# AST1080 register map
File version: 1.0
CPU: CM4 r0p1, little endian, MPU, FPU, 4 interrupt priority bits, 256 interrupts
Registers are 32-bit, read-write, reset 0x0 unless marked. A register's access mark holds for its fields unless they carry their own. Offsets are from the block's base; [hi:lo] are bit positions; {n}, {i} and the like mark numbered series; 'fields as' and 'values as' point back to an identical list.

## uartdma
Base 0x74C12000
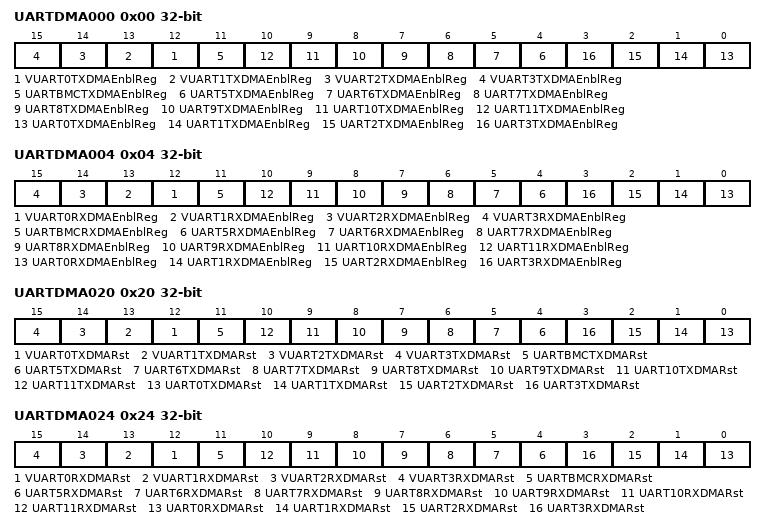
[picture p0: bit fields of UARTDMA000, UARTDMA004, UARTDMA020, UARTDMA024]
0x00 UARTDMA000 — UART TX DMA enable
  [n+12] VUART{n}TXDMAEnblReg (n=0..3) — VUART{n} TX DMA enable register
  [11] UARTBMCTXDMAEnblReg — UART-BMC TX DMA enable register
  [n-1] UART{n}TXDMAEnblReg (n=5..11) — UART{n} TX DMA enable register
  [n] UART{n}TXDMAEnblReg (n=0..3) — UART{n} TX DMA enable register
0x04 UARTDMA004 — UART RX DMA enable
  [n+12] VUART{n}RXDMAEnblReg (n=0..3) — VUART{n} RX DMA enable register
  [11] UARTBMCRXDMAEnblReg — UART-BMC RX DMA enable register
  [n-1] UART{n}RXDMAEnblReg (n=5..11) — UART{n} RX DMA enable register
  [n] UART{n}RXDMAEnblReg (n=0..3) — UART{n} RX DMA enable register
0x08 UARTDMA008 — Misc control
  [4] DisableTimeOut
    0=Enable_Time_Out_Timer; 1=Disable_Time_Out_Timer
0x0C UARTDMA00C — UART DMA time out timer
  [15:0] UARTDMATimeOutTimer
0x20 UARTDMA020 — UART TX DMA reset
  [n+12] VUART{n}TXDMARst (n=0..3) — VUART{n} TX DMA reset
  [11] UARTBMCTXDMARst — UART-BMC TX DMA reset
  [n-1] UART{n}TXDMARst (n=5..11) — UART{n} TX DMA reset
  [n] UART{n}TXDMARst (n=0..3) — UART{n} TX DMA reset
0x24 UARTDMA024 — UART RX DMA reset
  [n+12] VUART{n}RXDMARst (n=0..3) — VUART{n} RX DMA reset
  [11] UARTBMCRXDMARst — UART-BMC RX DMA reset
  [n-1] UART{n}RXDMARst (n=5..11) — UART{n} RX DMA reset
  [n] UART{n}RXDMARst (n=0..3) — UART{n} RX DMA reset
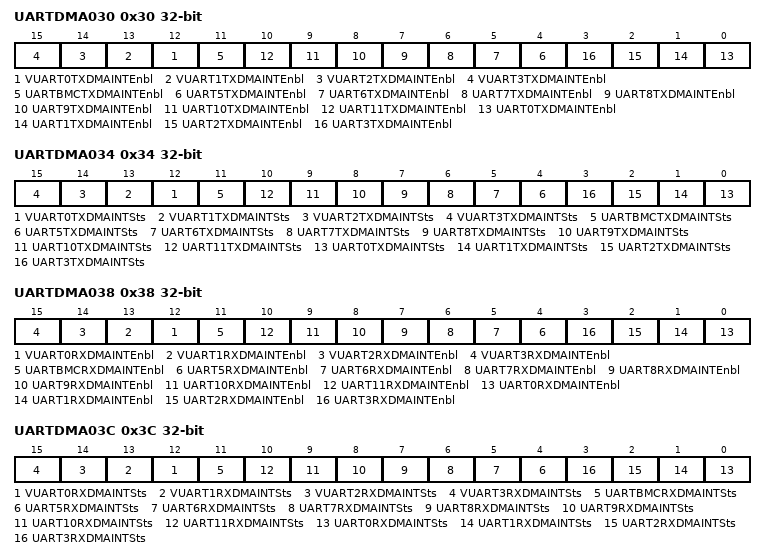
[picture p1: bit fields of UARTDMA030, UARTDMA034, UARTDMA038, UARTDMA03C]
0x30 UARTDMA030 — UART TX DMA interrrupt enable
  [n+12] VUART{n}TXDMAINTEnbl (n=0..3) — VUART{n} TX DMA interrupt enable
  [11] UARTBMCTXDMAINTEnbl — UART-BMC TX DMA interrupt enable
  [n-1] UART{n}TXDMAINTEnbl (n=5..11) — UART{n} TX DMA interrupt enable
  [n] UART{n}TXDMAINTEnbl (n=0..3) — UART{n} TX DMA interrupt enable
0x34 UARTDMA034 — UART TX DMA interrrupt status
  [n+12] VUART{n}TXDMAINTSts (n=0..3) — VUART{n} TX DMA interrupt status
  [11] UARTBMCTXDMAINTSts — UART-BMC TX DMA interrupt status
  [n-1] UART{n}TXDMAINTSts (n=5..11) — UART{n} TX DMA interrupt status
  [n] UART{n}TXDMAINTSts (n=0..3) — UART{n} TX DMA interrupt status
0x38 UARTDMA038 — UART RX DMA interrrupt enable
  [n+12] VUART{n}RXDMAINTEnbl (n=0..3) — VUART{n} RX DMA interrupt enable
  [11] UARTBMCRXDMAINTEnbl — UART-BMC RX DMA interrupt enable
  [n-1] UART{n}RXDMAINTEnbl (n=5..11) — UART{n} RX DMA interrupt enable
  [n] UART{n}RXDMAINTEnbl (n=0..3) — UART{n} RX DMA interrupt enable
0x3C UARTDMA03C — UART RX DMA interrrupt status
  [n+12] VUART{n}RXDMAINTSts (n=0..3) — VUART{n} RX DMA interrupt status
  [11] UARTBMCRXDMAINTSts — UART-BMC RX DMA interrupt status
  [n-1] UART{n}RXDMAINTSts (n=5..11) — UART{n} RX DMA interrupt status
  [n] UART{n}RXDMAINTSts (n=0..3) — UART{n} RX DMA interrupt status
0x40 UARTDMA040 — UART0 TX read pointer
  [15:0] UART0TXReadPointer ro
0x44 UARTDMA044 — UART0 TX write pointer
  [15:0] UART0TXWrPointer
0x48 UARTDMA048 — UART0 TX buffer base address
  [31:2] UART0TXBufBaseAddr
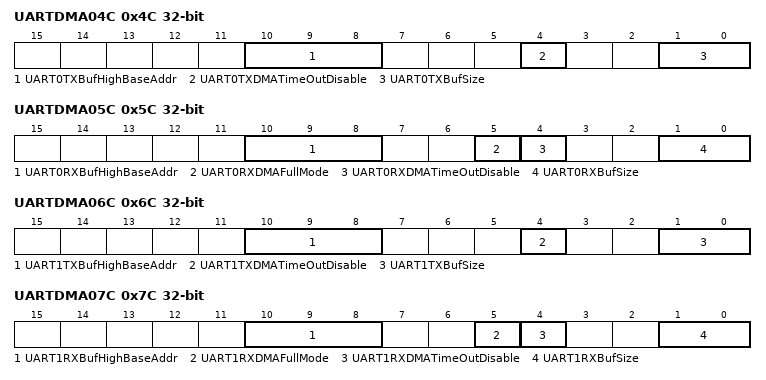
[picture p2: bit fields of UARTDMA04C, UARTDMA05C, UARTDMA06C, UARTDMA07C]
0x4C UARTDMA04C — UART0 TX control register
  [10:8] UART0TXBufHighBaseAddr — UART0 TX buffer high base address
  [4] UART0TXDMATimeOutDisable
    0=The_TX_DMA_Will_Not_Start_To_Transmit_Until_At_Least_A_Full_Double_Word_Data_In_TX_Buffer_Or_Time_Out; 1=Time_Out_Is_Disabled
  [1:0] UART0TXBufSize — UART0 TX buffer size
    0=1KB; 1=4KB; 2=16KB; 3=64KB
0x50 UARTDMA050 — UART0 RX read pointer
  [15:0] UART0RXReadPointer
0x54 UARTDMA054 — UART0 RX write pointer
  [16:0] UART0RXWrPointer ro
0x58 UARTDMA058 — UART0 RX buffer base address
  [31:2] UART0RXBufBaseAddr
0x5C UARTDMA05C — UART0 RX control register
  [10:8] UART0RXBufHighBaseAddr — UART0 RX buffer high base address
  [5] UART0RXDMAFullMode
    0=RX_Buffer_Is_Full_When_RX_Read_Pointer_Is_Equal_To_RX_Write_Pointer_Minus_1_This_Is_Used_For_Ring_Buffer_Mode; 1=RX_Buffer_Is_Full_When_RX_Write_Pointer_Is_Equal_To_Or_Greater_Than_RX_Write_Pointer_This_Is_Used_For_Single_Buffer_Mode
  [4] UART0RXDMATimeOutDisable
    0=The_RX_DMA_Will_Assert_Interrupt_When_RX_Buffer_Is_Full_Or_RX_Buffer_Is_Not_Empty_And_Time_Out; 1=Time_Out_Is_Disabled_The_RX_DMA_Will_Assert_Interrupt_Only_When_RX_Buffer_Is_Full
  [1:0] UART0RXBufSize — UART0 RX buffer size
    0=1KB; 1=4KB; 2=16KB; 3=64KB
0x60 UARTDMA060 — UART1 TX read pointer
  [15:0] UART1TXReadPointer ro
0x64 UARTDMA064 — UART1 TX write pointer
  [15:0] UART1TXWrPointer
0x68 UARTDMA068 — UART1 TX buffer base address
  [31:2] UART1TXBufBaseAddr
0x6C UARTDMA06C — UART1 TX control register
  [10:8] UART1TXBufHighBaseAddr — UART1 TX buffer high base address
  [4] UART1TXDMATimeOutDisable
    values as UARTDMA04C.UART0TXDMATimeOutDisable
  [1:0] UART1TXBufSize — UART1 TX buffer size
    0=1KB; 1=4KB; 2=16KB; 3=64KB
0x70 UARTDMA070 — UART1 RX read pointer
  [15:0] UART1RXReadPointer
0x74 UARTDMA074 — UART1 RX write pointer
  [16:0] UART1RXWrPointer ro
0x78 UARTDMA078 — UART1 RX buffer base address
  [31:2] UART1RXBufBaseAddr
0x7C UARTDMA07C — UART1 RX control register
  [10:8] UART1RXBufHighBaseAddr — UART1 RX buffer high base address
  [5] UART1RXDMAFullMode
    values as UARTDMA05C.UART0RXDMAFullMode
  [4] UART1RXDMATimeOutDisable
    values as UARTDMA05C.UART0RXDMATimeOutDisable
  [1:0] UART1RXBufSize — UART1 RX buffer size
    0=1KB; 1=4KB; 2=16KB; 3=64KB
0x80 UARTDMA080 — UART2 TX read pointer
  [15:0] UART2TXReadPointer ro
0x84 UARTDMA084 — UART2 TX write pointer
  [15:0] UART2TXWrPointer
0x88 UARTDMA088 — UART2 TX buffer base address
  [31:2] UART2TXBufBaseAddr
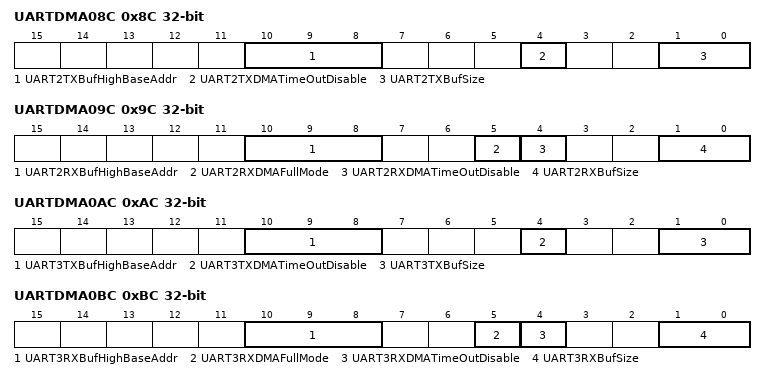
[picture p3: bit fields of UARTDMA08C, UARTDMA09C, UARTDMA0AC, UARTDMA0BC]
0x8C UARTDMA08C — UART2 TX control register
  [10:8] UART2TXBufHighBaseAddr — UART2 TX buffer high base address
  [4] UART2TXDMATimeOutDisable
    values as UARTDMA04C.UART0TXDMATimeOutDisable
  [1:0] UART2TXBufSize — UART2 TX buffer size
    0=1KB; 1=4KB; 2=16KB; 3=64KB
0x90 UARTDMA090 — UART2 RX read pointer
  [15:0] UART2RXReadPointer
0x94 UARTDMA094 — UART2 RX write pointer
  [16:0] UART2RXWrPointer ro
0x98 UARTDMA098 — UART2 RX buffer base address
  [31:2] UART2RXBufBaseAddr
0x9C UARTDMA09C — UART2 RX control register
  [10:8] UART2RXBufHighBaseAddr — UART2 RX buffer high base address
  [5] UART2RXDMAFullMode
    values as UARTDMA05C.UART0RXDMAFullMode
  [4] UART2RXDMATimeOutDisable
    values as UARTDMA05C.UART0RXDMATimeOutDisable
  [1:0] UART2RXBufSize — UART2 RX buffer size
    0=1KB; 1=4KB; 2=16KB; 3=64KB
0xA0 UARTDMA0A0 — UART3 TX read pointer
  [15:0] UART3TXReadPointer ro
0xA4 UARTDMA0A4 — UART3 TX write pointer
  [15:0] UART3TXWrPointer
0xA8 UARTDMA0A8 — UART3 TX buffer base address
  [31:2] UART3TXBufBaseAddr
0xAC UARTDMA0AC — UART3 TX control register
  [10:8] UART3TXBufHighBaseAddr — UART3 TX buffer high base address
  [4] UART3TXDMATimeOutDisable
    values as UARTDMA04C.UART0TXDMATimeOutDisable
  [1:0] UART3TXBufSize — UART3 TX buffer size
    0=1KB; 1=4KB; 2=16KB; 3=64KB
0xB0 UARTDMA0B0 — UART3 RX read pointer
  [15:0] UART3RXReadPointer
0xB4 UARTDMA0B4 — UART3 RX write pointer
  [16:0] UART3RXWrPointer ro
0xB8 UARTDMA0B8 — UART3 RX buffer base address
  [31:2] UART3RXBufBaseAddr
0xBC UARTDMA0BC — UART3 RX control register
  [10:8] UART3RXBufHighBaseAddr — UART3 RX buffer high base address
  [5] UART3RXDMAFullMode
    values as UARTDMA05C.UART0RXDMAFullMode
  [4] UART3RXDMATimeOutDisable
    values as UARTDMA05C.UART0RXDMATimeOutDisable
  [1:0] UART3RXBufSize — UART3 RX buffer size
    0=1KB; 1=4KB; 2=16KB; 3=64KB
0xC0 UARTDMA0C0 — UART5 TX read pointer
  [15:0] UART5TXReadPointer ro
0xC4 UARTDMA0C4 — UART5 TX write pointer
  [15:0] UART5TXWrPointer
0xC8 UARTDMA0C8 — UART5 TX buffer base address
  [31:2] UART5TXBufBaseAddr
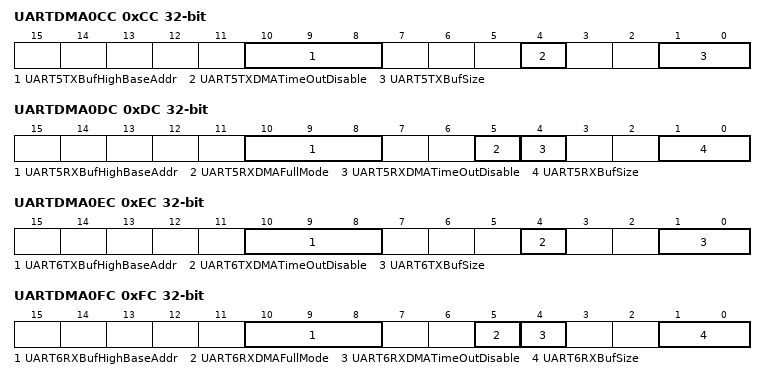
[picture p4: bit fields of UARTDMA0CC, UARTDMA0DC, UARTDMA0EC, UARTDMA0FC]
0xCC UARTDMA0CC — UART5 TX control register
  [10:8] UART5TXBufHighBaseAddr — UART5 TX buffer high base address
  [4] UART5TXDMATimeOutDisable
    values as UARTDMA04C.UART0TXDMATimeOutDisable
  [1:0] UART5TXBufSize — UART5 TX buffer size
    0=1KB; 1=4KB; 2=16KB; 3=64KB
0xD0 UARTDMA0D0 — UART5 RX read pointer
  [15:0] UART5RXReadPointer
0xD4 UARTDMA0D4 — UART5 RX write pointer
  [16:0] UART5RXWrPointer ro
0xD8 UARTDMA0D8 — UART5 RX buffer base address
  [31:2] UART5RXBufBaseAddr
0xDC UARTDMA0DC — UART5 RX control register
  [10:8] UART5RXBufHighBaseAddr — UART5 RX buffer high base address
  [5] UART5RXDMAFullMode
    values as UARTDMA05C.UART0RXDMAFullMode
  [4] UART5RXDMATimeOutDisable
    values as UARTDMA05C.UART0RXDMATimeOutDisable
  [1:0] UART5RXBufSize — UART5 RX buffer size
    0=1KB; 1=4KB; 2=16KB; 3=64KB
0xE0 UARTDMA0E0 — UART6 TX read pointer
  [15:0] UART6TXReadPointer ro
0xE4 UARTDMA0E4 — UART6 TX write pointer
  [15:0] UART6TXWrPointer
0xE8 UARTDMA0E8 — UART6 TX buffer base address
  [31:2] UART6TXBufBaseAddr
0xEC UARTDMA0EC — UART6 TX control register
  [10:8] UART6TXBufHighBaseAddr — UART6 TX buffer high base address
  [4] UART6TXDMATimeOutDisable
    values as UARTDMA04C.UART0TXDMATimeOutDisable
  [1:0] UART6TXBufSize — UART6 TX buffer size
    0=1KB; 1=4KB; 2=16KB; 3=64KB
0xF0 UARTDMA0F0 — UART6 RX read pointer
  [15:0] UART6RXReadPointer
0xF4 UARTDMA0F4 — UART6 RX write pointer
  [16:0] UART6RXWrPointer ro
0xF8 UARTDMA0F8 — UART6 RX buffer base address
  [31:2] UART6RXBufBaseAddr
0xFC UARTDMA0FC — UART6 RX control register
  [10:8] UART6RXBufHighBaseAddr — UART6 RX buffer high base address
  [5] UART6RXDMAFullMode
    values as UARTDMA05C.UART0RXDMAFullMode
  [4] UART6RXDMATimeOutDisable
    values as UARTDMA05C.UART0RXDMATimeOutDisable
  [1:0] UART6RXBufSize — UART6 RX buffer size
    0=1KB; 1=4KB; 2=16KB; 3=64KB
0x100 UARTDMA100 — UART7 TX read pointer
  [15:0] UART7TXReadPointer ro
0x104 UARTDMA104 — UART7 TX write pointer
  [15:0] UART7TXWrPointer
0x108 UARTDMA108 — UART7 TX buffer base address
  [31:2] UART7TXBufBaseAddr
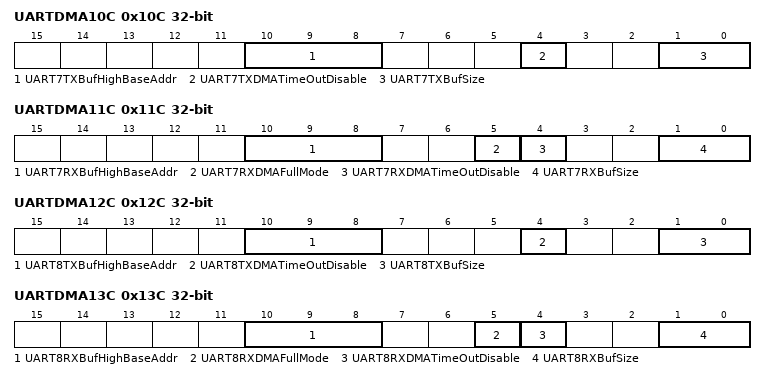
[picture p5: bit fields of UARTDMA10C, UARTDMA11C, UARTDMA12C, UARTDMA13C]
0x10C UARTDMA10C — UART7 TX control register
  [10:8] UART7TXBufHighBaseAddr — UART7 TX buffer high base address
  [4] UART7TXDMATimeOutDisable
    values as UARTDMA04C.UART0TXDMATimeOutDisable
  [1:0] UART7TXBufSize — UART7 TX buffer size
    0=1KB; 1=4KB; 2=16KB; 3=64KB
0x110 UARTDMA110 — UART7 RX read pointer
  [15:0] UART7RXReadPointer
0x114 UARTDMA114 — UART7 RX write pointer
  [16:0] UART7RXWrPointer ro
0x118 UARTDMA118 — UART7 RX buffer base address
  [31:2] UART7RXBufBaseAddr
0x11C UARTDMA11C — UART7 RX control register
  [10:8] UART7RXBufHighBaseAddr — UART7 RX buffer high base address
  [5] UART7RXDMAFullMode
    values as UARTDMA05C.UART0RXDMAFullMode
  [4] UART7RXDMATimeOutDisable
    values as UARTDMA05C.UART0RXDMATimeOutDisable
  [1:0] UART7RXBufSize — UART7 RX buffer size
    0=1KB; 1=4KB; 2=16KB; 3=64KB
0x120 UARTDMA120 — UART8 TX read pointer
  [15:0] UART8TXReadPointer ro
0x124 UARTDMA124 — UART8 TX write pointer
  [15:0] UART8TXWrPointer
0x128 UARTDMA128 — UART8 TX buffer base address
  [31:2] UART8TXBufBaseAddr
0x12C UARTDMA12C — UART8 TX control register
  [10:8] UART8TXBufHighBaseAddr — UART8 TX buffer high base address
  [4] UART8TXDMATimeOutDisable
    values as UARTDMA04C.UART0TXDMATimeOutDisable
  [1:0] UART8TXBufSize — UART8 TX buffer size
    0=1KB; 1=4KB; 2=16KB; 3=64KB
0x130 UARTDMA130 — UART8 RX read pointer
  [15:0] UART8RXReadPointer
0x134 UARTDMA134 — UART8 RX write pointer
  [16:0] UART8RXWrPointer ro
0x138 UARTDMA138 — UART8 RX buffer base address
  [31:2] UART8RXBufBaseAddr
0x13C UARTDMA13C — UART8 RX control register
  [10:8] UART8RXBufHighBaseAddr — UART8 RX buffer high base address
  [5] UART8RXDMAFullMode
    values as UARTDMA05C.UART0RXDMAFullMode
  [4] UART8RXDMATimeOutDisable
    values as UARTDMA05C.UART0RXDMATimeOutDisable
  [1:0] UART8RXBufSize — UART8 RX buffer size
    0=1KB; 1=4KB; 2=16KB; 3=64KB
0x140 UARTDMA140 — UART9 TX read pointer
  [15:0] UART9TXReadPointer ro
0x144 UARTDMA144 — UART9 TX write pointer
  [15:0] UART9TXWrPointer
0x148 UARTDMA148 — UART9 TX buffer base address
  [31:2] UART9TXBufBaseAddr
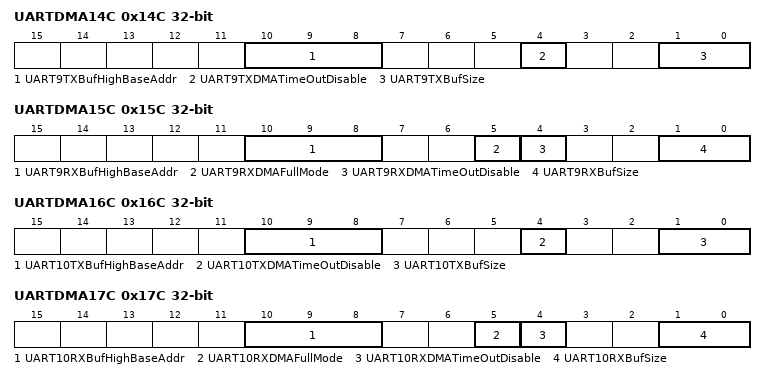
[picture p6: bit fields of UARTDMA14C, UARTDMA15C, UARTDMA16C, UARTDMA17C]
0x14C UARTDMA14C — UART9 TX control register
  [10:8] UART9TXBufHighBaseAddr — UART9 TX buffer high base address
  [4] UART9TXDMATimeOutDisable
    values as UARTDMA04C.UART0TXDMATimeOutDisable
  [1:0] UART9TXBufSize — UART9 TX buffer size
    0=1KB; 1=4KB; 2=16KB; 3=64KB
0x150 UARTDMA150 — UART9 RX read pointer
  [15:0] UART9RXReadPointer
0x154 UARTDMA154 — UART9 RX write pointer
  [16:0] UART9RXWrPointer ro
0x158 UARTDMA158 — UART9 RX buffer base address
  [31:2] UART9RXBufBaseAddr
0x15C UARTDMA15C — UART9 RX control register
  [10:8] UART9RXBufHighBaseAddr — UART9 RX buffer high base address
  [5] UART9RXDMAFullMode
    values as UARTDMA05C.UART0RXDMAFullMode
  [4] UART9RXDMATimeOutDisable
    values as UARTDMA05C.UART0RXDMATimeOutDisable
  [1:0] UART9RXBufSize — UART9 RX buffer size
    0=1KB; 1=4KB; 2=16KB; 3=64KB
0x160 UARTDMA160 — UART10 TX read pointer
  [15:0] UART10TXReadPointer ro
0x164 UARTDMA164 — UART10 TX write pointer
  [15:0] UART10TXWrPointer
0x168 UARTDMA168 — UART10 TX buffer base address
  [31:2] UART10TXBufBaseAddr
0x16C UARTDMA16C — UART10 TX control register
  [10:8] UART10TXBufHighBaseAddr — UART10 TX buffer high base address
  [4] UART10TXDMATimeOutDisable
    values as UARTDMA04C.UART0TXDMATimeOutDisable
  [1:0] UART10TXBufSize — UART10 TX buffer size
    0=1KB; 1=4KB; 2=16KB; 3=64KB
0x170 UARTDMA170 — UART10 RX read pointer
  [15:0] UART10RXReadPointer
0x174 UARTDMA174 — UART10 RX write pointer
  [16:0] UART10RXWrPointer ro
0x178 UARTDMA178 — UART10 RX buffer base address
  [31:2] UART10RXBufBaseAddr
0x17C UARTDMA17C — UART10 RX control register
  [10:8] UART10RXBufHighBaseAddr — UART10 RX buffer high base address
  [5] UART10RXDMAFullMode
    values as UARTDMA05C.UART0RXDMAFullMode
  [4] UART10RXDMATimeOutDisable
    values as UARTDMA05C.UART0RXDMATimeOutDisable
  [1:0] UART10RXBufSize — UART10 RX buffer size
    0=1KB; 1=4KB; 2=16KB; 3=64KB
0x180 UARTDMA180 — UART11 TX read pointer
  [15:0] UART11TXReadPointer ro
0x184 UARTDMA184 — UART11 TX write pointer
  [15:0] UART11TXWrPointer
0x188 UARTDMA188 — UART11 TX buffer base address
  [31:2] UART11TXBufBaseAddr
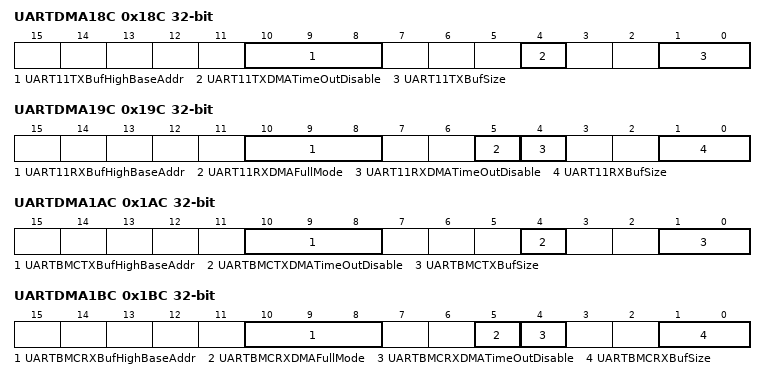
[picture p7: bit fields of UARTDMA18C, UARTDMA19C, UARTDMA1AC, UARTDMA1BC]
0x18C UARTDMA18C — UART11 TX control register
  [10:8] UART11TXBufHighBaseAddr — UART11 TX buffer high base address
  [4] UART11TXDMATimeOutDisable
    values as UARTDMA04C.UART0TXDMATimeOutDisable
  [1:0] UART11TXBufSize — UART11 TX buffer size
    0=1KB; 1=4KB; 2=16KB; 3=64KB
0x190 UARTDMA190 — UART11 RX read pointer
  [15:0] UART11RXReadPointer
0x194 UARTDMA194 — UART11 RX write pointer
  [16:0] UART11RXWrPointer ro
0x198 UARTDMA198 — UART11 RX buffer base address
  [31:2] UART11RXBufBaseAddr
0x19C UARTDMA19C — UART11 RX control register
  [10:8] UART11RXBufHighBaseAddr — UART11 RX buffer high base address
  [5] UART11RXDMAFullMode
    values as UARTDMA05C.UART0RXDMAFullMode
  [4] UART11RXDMATimeOutDisable
    values as UARTDMA05C.UART0RXDMATimeOutDisable
  [1:0] UART11RXBufSize — UART11 RX buffer size
    0=1KB; 1=4KB; 2=16KB; 3=64KB
0x1A0 UARTDMA1A0 — UART-BMC TX read pointer
  [15:0] UARTBMCTXReadPointer ro
0x1A4 UARTDMA1A4 — UART-BMC TX write pointer
  [15:0] UARTBMCTXWrPointer
0x1A8 UARTDMA1A8 — UART-BMC TX buffer base address
  [31:2] UARTBMCTXBufBaseAddr
0x1AC UARTDMA1AC — UART-BMC TX control register
  [10:8] UARTBMCTXBufHighBaseAddr — UART-BMC TX buffer high base address
  [4] UARTBMCTXDMATimeOutDisable
    values as UARTDMA04C.UART0TXDMATimeOutDisable
  [1:0] UARTBMCTXBufSize — UART-BMC TX buffer size
    0=1KB; 1=4KB; 2=16KB; 3=64KB
0x1B0 UARTDMA1B0 — UART-BMC RX read pointer
  [15:0] UARTBMCRXReadPointer
0x1B4 UARTDMA1B4 — UART-BMC RX write pointer
  [16:0] UARTBMCRXWrPointer ro
0x1B8 UARTDMA1B8 — UART-BMC RX buffer base address
  [31:2] UARTBMCRXBufBaseAddr
0x1BC UARTDMA1BC — UART-BMC RX control register
  [10:8] UARTBMCRXBufHighBaseAddr — UART-BMC RX buffer high base address
  [5] UARTBMCRXDMAFullMode
    values as UARTDMA05C.UART0RXDMAFullMode
  [4] UARTBMCRXDMATimeOutDisable
    values as UARTDMA05C.UART0RXDMATimeOutDisable
  [1:0] UARTBMCRXBufSize — UART-BMC RX buffer size
    0=1KB; 1=4KB; 2=16KB; 3=64KB
0x1C0 UARTDMA1C0 — VUART0 TX read pointer
  [23:0] VUART0TXReadPointer ro
0x1C4 UARTDMA1C4 — VUART0 TX write pointer
  [23:0] VUART0TXWrPointer
0x1C8 UARTDMA1C8 — VUART0 TX buffer base address
  [31:2] VUART0TXBufBaseAddr
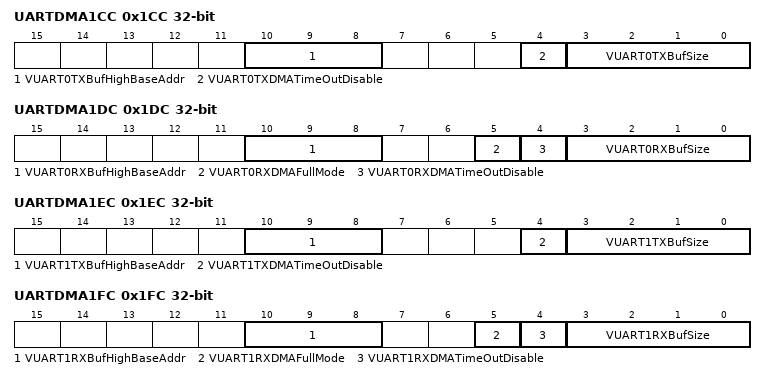
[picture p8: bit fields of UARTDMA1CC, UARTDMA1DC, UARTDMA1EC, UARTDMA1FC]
0x1CC UARTDMA1CC — VUART0 TX control register
  [10:8] VUART0TXBufHighBaseAddr — VUART0 TX buffer high base address
  [4] VUART0TXDMATimeOutDisable
    values as UARTDMA04C.UART0TXDMATimeOutDisable
  [3:0] VUART0TXBufSize — VUART0 TX buffer size
    0=1KB; 1=4KB; 2=16KB; 3=64KB; 4=128KB; 5=256KB; 6=512KB; 7=1024KB; 8=2048KB; 9=4096KB; 10=8192KB; 11=16384KB
0x1D0 UARTDMA1D0 — VUART0 RX read pointer
  [23:0] VUART0RXReadPointer
0x1D4 UARTDMA1D4 — VUART0 RX write pointer
  [24:0] VUART0RXWrPointer ro
0x1D8 UARTDMA1D8 — VUART0 RX buffer base address
  [31:2] VUART0RXBufBaseAddr
0x1DC UARTDMA1DC — VUART0 RX control register
  [10:8] VUART0RXBufHighBaseAddr — VUART0 RX buffer high base address
  [5] VUART0RXDMAFullMode
    values as UARTDMA05C.UART0RXDMAFullMode
  [4] VUART0RXDMATimeOutDisable
    values as UARTDMA05C.UART0RXDMATimeOutDisable
  [3:0] VUART0RXBufSize — VUART0 RX buffer size
    values as UARTDMA1CC.VUART0TXBufSize
0x1E0 UARTDMA1E0 — VUART1 TX read pointer
  [23:0] VUART1TXReadPointer ro
0x1E4 UARTDMA1E4 — VUART1 TX write pointer
  [23:0] VUART1TXWrPointer
0x1E8 UARTDMA1E8 — VUART1 TX buffer base address
  [31:2] VUART1TXBufBaseAddr
0x1EC UARTDMA1EC — VUART1 TX control register
  [10:8] VUART1TXBufHighBaseAddr — VUART1 TX buffer high base address
  [4] VUART1TXDMATimeOutDisable
    values as UARTDMA04C.UART0TXDMATimeOutDisable
  [3:0] VUART1TXBufSize — VUART1 TX buffer size
    values as UARTDMA1CC.VUART0TXBufSize
0x1F0 UARTDMA1F0 — VUART1 RX read pointer
  [23:0] VUART1RXReadPointer
0x1F4 UARTDMA1F4 — VUART1 RX write pointer
  [24:0] VUART1RXWrPointer ro
0x1F8 UARTDMA1F8 — VUART1 RX buffer base address
  [31:2] VUART1RXBufBaseAddr
0x1FC UARTDMA1FC — VUART1 RX control register
  [10:8] VUART1RXBufHighBaseAddr — VUART1 RX buffer high base address
  [5] VUART1RXDMAFullMode
    values as UARTDMA05C.UART0RXDMAFullMode
  [4] VUART1RXDMATimeOutDisable
    values as UARTDMA05C.UART0RXDMATimeOutDisable
  [3:0] VUART1RXBufSize — VUART1 RX buffer size
    values as UARTDMA1CC.VUART0TXBufSize
0x200 UARTDMA200 — VUART2 TX read pointer
  [23:0] VUART2TXReadPointer ro
0x204 UARTDMA204 — VUART2 TX write pointer
  [23:0] VUART2TXWrPointer
0x208 UARTDMA208 — VUART2 TX buffer base address
  [31:2] VUART2TXBufBaseAddr
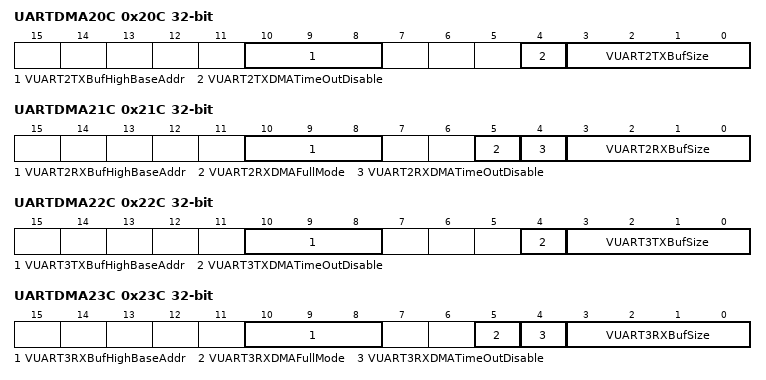
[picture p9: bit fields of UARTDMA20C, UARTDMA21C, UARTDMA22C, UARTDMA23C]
0x20C UARTDMA20C — VUART2 TX control register
  [10:8] VUART2TXBufHighBaseAddr — VUART2 TX buffer high base address
  [4] VUART2TXDMATimeOutDisable
    values as UARTDMA04C.UART0TXDMATimeOutDisable
  [3:0] VUART2TXBufSize — VUART2 TX buffer size
    values as UARTDMA1CC.VUART0TXBufSize
0x210 UARTDMA210 — VUART2 RX read pointer
  [23:0] VUART2RXReadPointer
0x214 UARTDMA214 — VUART2 RX write pointer
  [24:0] VUART2RXWrPointer ro
0x218 UARTDMA218 — VUART2 RX buffer base address
  [31:2] VUART2RXBufBaseAddr
0x21C UARTDMA21C — VUART2 RX control register
  [10:8] VUART2RXBufHighBaseAddr — VUART2 RX buffer high base address
  [5] VUART2RXDMAFullMode
    values as UARTDMA05C.UART0RXDMAFullMode
  [4] VUART2RXDMATimeOutDisable
    values as UARTDMA05C.UART0RXDMATimeOutDisable
  [3:0] VUART2RXBufSize — VUART2 RX buffer size
    values as UARTDMA1CC.VUART0TXBufSize
0x220 UARTDMA220 — VUART3 TX read pointer
  [23:0] VUART3TXReadPointer ro
0x224 UARTDMA224 — VUART3 TX write pointer
  [23:0] VUART3TXWrPointer
0x228 UARTDMA228 — VUART3 TX buffer base address
  [31:2] VUART3TXBufBaseAddr
0x22C UARTDMA22C — VUART3 TX control register
  [10:8] VUART3TXBufHighBaseAddr — VUART3 TX buffer high base address
  [4] VUART3TXDMATimeOutDisable
    values as UARTDMA04C.UART0TXDMATimeOutDisable
  [3:0] VUART3TXBufSize — VUART3 TX buffer size
    values as UARTDMA1CC.VUART0TXBufSize
0x230 UARTDMA230 — VUART3 RX read pointer
  [23:0] VUART3RXReadPointer
0x234 UARTDMA234 — VUART3 RX write pointer
  [24:0] VUART3RXWrPointer ro
0x238 UARTDMA238 — VUART3 RX buffer base address
  [31:2] VUART3RXBufBaseAddr
0x23C UARTDMA23C — VUART3 RX control register
  [10:8] VUART3RXBufHighBaseAddr — VUART3 RX buffer high base address
  [5] VUART3RXDMAFullMode
    values as UARTDMA05C.UART0RXDMAFullMode
  [4] VUART3RXDMATimeOutDisable
    values as UARTDMA05C.UART0RXDMATimeOutDisable
  [3:0] VUART3RXBufSize — VUART3 RX buffer size
    values as UARTDMA1CC.VUART0TXBufSize
